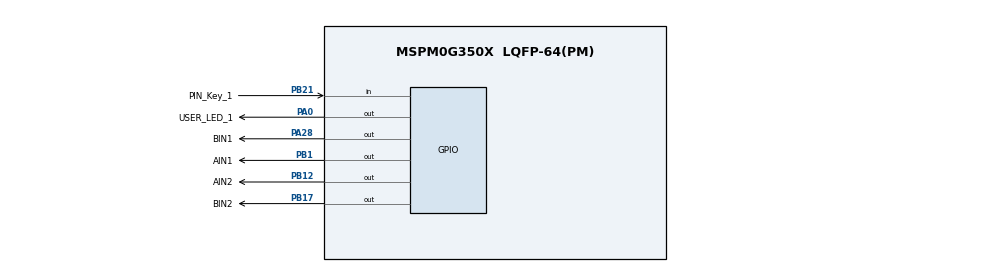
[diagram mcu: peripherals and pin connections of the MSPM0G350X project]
/**
 * @cliArgs --device "MSPM0G350X" --part "Default" --package "LQFP-64(PM)" --product "mspm0_sdk@2.10.00.04"
 * @versions {"tool":"1.27.1+4634"}
 */

/**
 * Import the modules used in this configuration.
 */
const GPIO   = scripting.addModule("/ti/driverlib/GPIO", {}, false);
const GPIO1  = GPIO.addInstance();
const GPIO2  = GPIO.addInstance();
const GPIO3  = GPIO.addInstance();
const PWM    = scripting.addModule("/ti/driverlib/PWM", {}, false);
const PWM1   = PWM.addInstance();
const SYSCTL = scripting.addModule("/ti/driverlib/SYSCTL");
const TIMER  = scripting.addModule("/ti/driverlib/TIMER", {}, false);
const TIMER1 = TIMER.addInstance();

/**
 * Write custom configuration values to the imported modules.
 */
GPIO1.$name                          = "GPIO_LED";
GPIO1.associatedPins[0].$name        = "USER_LED_1";
GPIO1.associatedPins[0].assignedPort = "PORTA";
GPIO1.associatedPins[0].pin.$assign  = "PA0";

const Board = scripting.addModule("/ti/driverlib/Board", {}, false);

GPIO2.$name                              = "GPIO_Key";
GPIO2.associatedPins[0].$name            = "PIN_Key_1";
GPIO2.associatedPins[0].assignedPort     = "PORTB";
GPIO2.associatedPins[0].assignedPin      = "21";
GPIO2.associatedPins[0].direction        = "INPUT";
GPIO2.associatedPins[0].internalResistor = "PULL_UP";
GPIO2.associatedPins[0].pin.$assign      = "PB21";

GPIO3.$name                         = "GPIO_TB6612";
GPIO3.associatedPins.create(4);
GPIO3.associatedPins[0].$name       = "AIN1";
GPIO3.associatedPins[0].pin.$assign = "PB1";
GPIO3.associatedPins[1].$name       = "AIN2";
GPIO3.associatedPins[1].pin.$assign = "PB12";
GPIO3.associatedPins[2].$name       = "BIN1";
GPIO3.associatedPins[2].pin.$assign = "PA28";
GPIO3.associatedPins[3].$name       = "BIN2";
GPIO3.associatedPins[3].pin.$assign = "PB17";

PWM1.$name                   = "PWM_0";
PWM1.clockDivider            = 8;
PWM1.clockPrescale           = 4;
PWM1.timerStartTimer         = true;
PWM1.peripheral.$assign      = "TIMG7";
PWM1.PWM_CHANNEL_0.$name     = "ti_driverlib_pwm_PWMTimerCC0";
PWM1.PWM_CHANNEL_0.dutyCycle = 50;
PWM1.PWM_CHANNEL_1.$name     = "ti_driverlib_pwm_PWMTimerCC1";
PWM1.ccp0PinConfig.$name     = "ti_driverlib_gpio_GPIOPinGeneric0";
PWM1.ccp1PinConfig.$name     = "ti_driverlib_gpio_GPIOPinGeneric1";

SYSCTL.forceDefaultClkConfig = true;

TIMER1.$name              = "TIMER_0";
TIMER1.timerClkDiv        = 8;
TIMER1.timerClkPrescale   = 100;
TIMER1.timerPeriod        = "1 ms";
TIMER1.timerStartTimer    = true;
TIMER1.interrupts         = ["ZERO"];
TIMER1.timerMode          = "PERIODIC";
TIMER1.peripheral.$assign = "TIMG0";

/**
 * Pinmux solution for unlocked pins/peripherals. This ensures that minor changes to the automatic solver in a future
 * version of the tool will not impact the pinmux you originally saw.  These lines can be completely deleted in order to
 * re-solve from scratch.
 */
Board.peripheral.$suggestSolution          = "DEBUGSS";
Board.peripheral.swclkPin.$suggestSolution = "PA20";
Board.peripheral.swdioPin.$suggestSolution = "PA19";
PWM1.peripheral.ccp0Pin.$suggestSolution   = "PA17";
PWM1.peripheral.ccp1Pin.$suggestSolution   = "PA18";
SYSCTL.peripheral.$suggestSolution         = "SYSCTL";
